# Ibex Demo System register map
Vendor: lowRISC; File version: 0.1
Single-core 3-stage pipeline RISC-V processor, 128 KiB on-chip SRAM. 1 x UART, 1 x SPI controller, 1 x PWM channels
CPU: Ibex r0p1, little endian, no MPU, no FPU, VTOR, 2 interrupt priority bits, 1 interrupts
Registers are 32-bit, read-write, reset 0x0 unless marked. A register's access mark holds for its fields unless they carry their own. Offsets are from the block's base; lines under a group give offsets from that group; [hi:lo] are bit positions; {n}, {i} and the like mark numbered series; 'fields as' and 'values as' point back to an identical list; <NAME> marks a mode.

## Memory map
0x80000000 GPIOA size 0x1000 — Gpio port a
0x80001000 UART0 size 0x1000
0x80002000 TIMER0 size 0x1000 — Controls timer
0x80003000 PWM0 size 0x8 — Simple PWM0
{0x80003000+8n} PWM{n} size 0x8 (n=2..11)
0x80004000 SPI0 size 0x1000
0x8000A008 PWM1 size 0x8

## Interrupts
0 GPIOA_IRQ (GPIOA)
1 UART0_RX_IRQ (UART0) — Indicates that there are bytes in RX FIFO ready to be received (i.e. not empty).
1 UART0_TX_IRQ (UART0) — Indicates that the TX FIFO is empty.
4 PWM_IRQ_WRAP (PWM0)
7 TIMER_IRQ_0 (TIMER0)
18 SPI0_IRQ (SPI0)
21 PWM{n}_IRQ_WRAP (PWM{n}) (n=2..11)
22 PWM1_IRQ_WRAP (PWM1)

## UART0
Base 0x80001000
0x00 RX ro — Rx register, UART_RX
  [7:0] DATA — Receive (read) data character. Transmit (write) data character.
0x04 TX wo — Tx register, UART_TX
  [7:0] DATA — Transmit (write) data character.
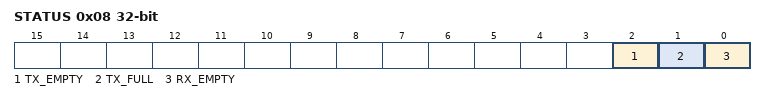
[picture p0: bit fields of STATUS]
0x08 STATUS ro — Uart Status Register, UART_STATUS
  [2] TX_EMPTY — 1 indicates that the TX FIFO is empty.
  [1] TX_FULL — 1 indicates that the TX FIFO is full.
  [0] RX_EMPTY — 1 indicates that the RX FIFO is empty.

## SPI0
Base 0x80004000
0x00 TX wo — Tx register, SPI_TX
  [7:0] DATA — Transmit (write) data character.
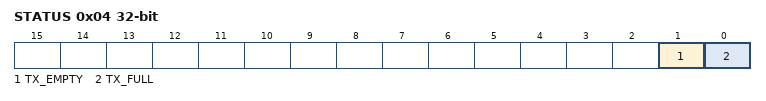
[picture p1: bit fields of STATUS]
0x04 STATUS ro — SPI Status Register, SPI_STATUS
  [1] TX_EMPTY — 1 indicates that the TX FIFO is empty.
  [0] TX_FULL — 1 indicates that the TX FIFO is full.

## PWM0 — Simple PWM0
Base 0x80003000
Same registers: PWM{n} {0x80003000+8n} (n=2..11), PWM1 0x8000A008
0x00 WIDTH — PWM width
  [31:0] VALUE — Pwm width.
0x04 COUNTER — PWM counter
  [31:0] VALUE — Pwm counter.

## TIMER0 — Controls timer
Base 0x80002000
0x00 MTIMEL — mtime low
  [31:0] VALUE
0x04 MTIMEH — mtime high
  [31:0] VALUE
0x08 MTIMECMPL — mtime cmp low
  [31:0] VALUE
0x0C MTIMECMPH — mtime cmp high
  [31:0] VALUE

## GPIOA — Gpio port a
Base 0x80000000
0x00 OUT — Write to control the gpio state
  [31:0] PINS
0x04 IN ro — Read the gpio state
  [31:0] PINS
0x08 IN_DBNC — DBNC
  [31:0] VALUE — DBNC.
0x0C OUT_SHIFT — Shift register
  [31:0] VALUE — Shift.

## Licence text in the file
Copyright lowRISC contributors. Licensed under the Apache License, Version 2.0, see LICENSE for details. SPDX-License-Identifier: Apache-2.0
